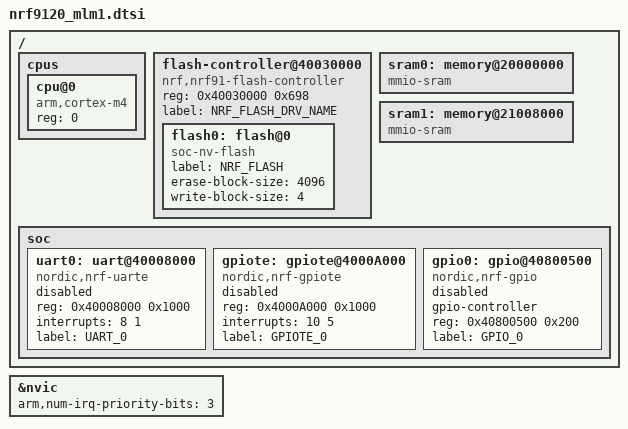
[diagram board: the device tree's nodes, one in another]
#include <arm/armv7-m.dtsi>

/ {
	cpus {
		#address-cells = <1>;
		#size-cells = <0>;

		cpu@0 {
			device_type = "cpu";
			compatible = "arm,cortex-m4";
			reg = <0>;
		};
	};

	flash-controller@40030000 {
			compatible = "nrf,nrf91-flash-controller";
			reg = <0x40030000 0x698>;

			#address-cells = <1>;
			#size-cells = <1>;

			label="NRF_FLASH_DRV_NAME";

			flash0: flash@0 {
				compatible = "soc-nv-flash";
				label = "NRF_FLASH";
				erase-block-size = <4096>;
				write-block-size = <4>;
			};
	};

	sram0: memory@20000000 {
		device_type = "memory";
		compatible = "mmio-sram";
	};

	sram1: memory@21008000 {
		device_type = "memory";
		compatible = "mmio-sram";
	};

	soc {
		uart0: uart@40008000 {
			compatible = "nordic,nrf-uarte";
			reg = <0x40008000 0x1000>;
			interrupts = <8 1>;
			status = "disabled";
			label = "UART_0";
		};

		gpiote: gpiote@4000A000 {
			compatible = "nordic,nrf-gpiote";
			reg = <0x4000A000 0x1000>;
			interrupts = <10 5>;
			interrupt-names = "gpiote";
			status = "disabled";
			label = "GPIOTE_0";
		};

		gpio0: gpio@40800500 {
			compatible = "nordic,nrf-gpio";
			gpio-controller;
			reg = <0x40800500 0x200>;
			#gpio-cells = <2>;
			label = "GPIO_0";
			status = "disabled";
		};
	};
};

&nvic {
	arm,num-irq-priority-bits = <3>;
};
